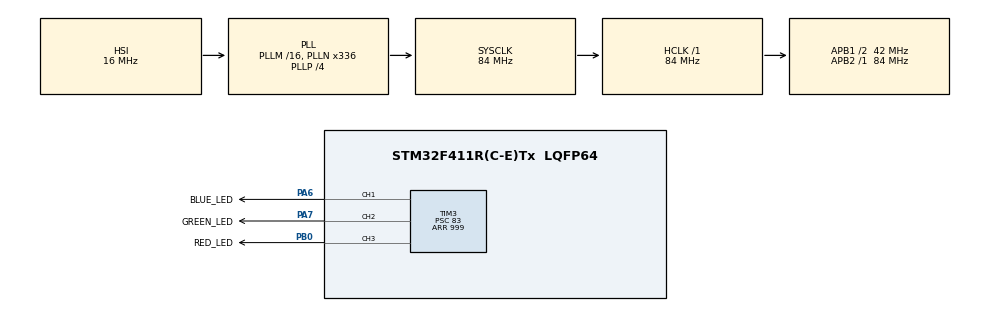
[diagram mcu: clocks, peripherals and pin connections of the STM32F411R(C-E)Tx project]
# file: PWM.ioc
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Mcu.Family=STM32F4
Mcu.Name=STM32F411R(C-E)Tx
Mcu.Package=LQFP64
NVIC.PriorityGroup=NVIC_PRIORITYGROUP_0
PA6.GPIO_Label=BLUE_LED
PA6.Signal=S_TIM3_CH1
PA7.GPIO_Label=GREEN_LED
PA7.Signal=S_TIM3_CH2
PB0.GPIO_Label=RED_LED
PB0.Signal=S_TIM3_CH3
ProjectManager.HeapSize=0x200
ProjectManager.StackSize=0x400
ProjectManager.TargetToolchain=STM32CubeIDE
RCC.48MHZClocksFreq_Value=84000000
RCC.AHBFreq_Value=84000000
RCC.APB1CLKDivider=RCC_HCLK_DIV2
RCC.APB1Freq_Value=42000000
RCC.APB1TimFreq_Value=84000000
RCC.APB2Freq_Value=84000000
RCC.APB2TimFreq_Value=84000000
RCC.CortexFreq_Value=84000000
RCC.FLatency-AdvancedSettings=FLASH_LATENCY_2
RCC.HCLKFreq_Value=84000000
RCC.HSE_VALUE=8000000
RCC.HSI_VALUE=16000000
RCC.PLLN=336
RCC.PLLP=RCC_PLLP_DIV4
RCC.SYSCLKFreq_VALUE=84000000
RCC.SYSCLKSource=RCC_SYSCLKSOURCE_PLLCLK
RCC.VCOOutputFreq_Value=336000000
SH.S_TIM3_CH1.0=TIM3_CH1,PWM Generation1 CH1
SH.S_TIM3_CH2.0=TIM3_CH2,PWM Generation2 CH2
SH.S_TIM3_CH3.0=TIM3_CH3,PWM Generation3 CH3
TIM3.AutoReloadPreload=TIM_AUTORELOAD_PRELOAD_ENABLE
TIM3.Channel-PWM\ Generation1\ CH1=TIM_CHANNEL_1
TIM3.Channel-PWM\ Generation2\ CH2=TIM_CHANNEL_2
TIM3.Channel-PWM\ Generation3\ CH3=TIM_CHANNEL_3
TIM3.Period=999
TIM3.Prescaler=83
board=NUCLEO-F411RE

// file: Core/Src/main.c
/* USER CODE BEGIN Header */
/**
  ******************************************************************************
  * @file           : main.c
  * @brief          : Main program body
  ******************************************************************************
  * @attention
  *
  * Copyright (c) 2026 STMicroelectronics.
  * All rights reserved.
  *
  * This software is licensed under terms that can be found in the LICENSE file
  * in the root directory of this software component.
  * If no LICENSE file comes with this software, it is provided AS-IS.
  *
  ******************************************************************************
  */
/* USER CODE END Header */
#include "main.h"

TIM_HandleTypeDef htim3;

void SystemClock_Config(void);
static void MX_GPIO_Init(void);
static void MX_TIM3_Init(void);

int main(void)
{

  /* MCU Configuration--------------------------------------------------------*/

  /* Reset of all peripherals, Initializes the Flash interface and the Systick. */
  HAL_Init();

  /* Configure the system clock */
  SystemClock_Config();

  /* Initialize all configured peripherals */
  MX_GPIO_Init();
  MX_TIM3_Init();
  /* USER CODE BEGIN 2 */

  HAL_TIM_PWM_Start(&htim3, TIM_CHANNEL_1);
  HAL_TIM_PWM_Start(&htim3, TIM_CHANNEL_2);
  HAL_TIM_PWM_Start(&htim3, TIM_CHANNEL_3);

  /* USER CODE END 2 */

  /* Infinite loop */

  while (1)
	  /* USER CODE BEGIN WHILE */
  {
	  for(int i = 0; i < 1000; i++)
	   {
	     __HAL_TIM_SET_COMPARE(&htim3, TIM_CHANNEL_1, i);        // Red ↑
	     __HAL_TIM_SET_COMPARE(&htim3, TIM_CHANNEL_2, 999 - i);  // Green ↓
	     __HAL_TIM_SET_COMPARE(&htim3, TIM_CHANNEL_3, i / 2);    // Blue medium

	     HAL_Delay(5);
	   }
  }
    /* USER CODE END WHILE */

}

void SystemClock_Config(void)
{
  RCC_OscInitTypeDef RCC_OscInitStruct = {0};
  RCC_ClkInitTypeDef RCC_ClkInitStruct = {0};

  /** Configure the main internal regulator output voltage
  */
  __HAL_RCC_PWR_CLK_ENABLE();
  __HAL_PWR_VOLTAGESCALING_CONFIG(PWR_REGULATOR_VOLTAGE_SCALE1);

  /** Initializes the RCC Oscillators according to the specified parameters
  * in the RCC_OscInitTypeDef structure.
  */
  RCC_OscInitStruct.OscillatorType = RCC_OSCILLATORTYPE_HSI;
  RCC_OscInitStruct.HSIState = RCC_HSI_ON;
  RCC_OscInitStruct.HSICalibrationValue = RCC_HSICALIBRATION_DEFAULT;
  RCC_OscInitStruct.PLL.PLLState = RCC_PLL_ON;
  RCC_OscInitStruct.PLL.PLLSource = RCC_PLLSOURCE_HSI;
  RCC_OscInitStruct.PLL.PLLM = 16;
  RCC_OscInitStruct.PLL.PLLN = 336;
  RCC_OscInitStruct.PLL.PLLP = RCC_PLLP_DIV4;
  RCC_OscInitStruct.PLL.PLLQ = 4;
  if (HAL_RCC_OscConfig(&RCC_OscInitStruct) != HAL_OK)
  {
    Error_Handler();
  }

  /** Initializes the CPU, AHB and APB buses clocks
  */
  RCC_ClkInitStruct.ClockType = RCC_CLOCKTYPE_HCLK|RCC_CLOCKTYPE_SYSCLK
                              |RCC_CLOCKTYPE_PCLK1|RCC_CLOCKTYPE_PCLK2;
  RCC_ClkInitStruct.SYSCLKSource = RCC_SYSCLKSOURCE_PLLCLK;
  RCC_ClkInitStruct.AHBCLKDivider = RCC_SYSCLK_DIV1;
  RCC_ClkInitStruct.APB1CLKDivider = RCC_HCLK_DIV2;
  RCC_ClkInitStruct.APB2CLKDivider = RCC_HCLK_DIV1;

  if (HAL_RCC_ClockConfig(&RCC_ClkInitStruct, FLASH_LATENCY_2) != HAL_OK)
  {
    Error_Handler();
  }
}

static void MX_TIM3_Init(void)
{

  TIM_MasterConfigTypeDef sMasterConfig = {0};
  TIM_OC_InitTypeDef sConfigOC = {0};

  htim3.Instance = TIM3;
  htim3.Init.Prescaler = 83;
  htim3.Init.CounterMode = TIM_COUNTERMODE_UP;
  htim3.Init.Period = 999;
  htim3.Init.ClockDivision = TIM_CLOCKDIVISION_DIV1;
  htim3.Init.AutoReloadPreload = TIM_AUTORELOAD_PRELOAD_ENABLE;
  if (HAL_TIM_PWM_Init(&htim3) != HAL_OK)
  {
    Error_Handler();
  }
  sMasterConfig.MasterOutputTrigger = TIM_TRGO_RESET;
  sMasterConfig.MasterSlaveMode = TIM_MASTERSLAVEMODE_DISABLE;
  if (HAL_TIMEx_MasterConfigSynchronization(&htim3, &sMasterConfig) != HAL_OK)
  {
    Error_Handler();
  }
  sConfigOC.OCMode = TIM_OCMODE_PWM1;
  sConfigOC.Pulse = 0;
  sConfigOC.OCPolarity = TIM_OCPOLARITY_HIGH;
  sConfigOC.OCFastMode = TIM_OCFAST_DISABLE;
  if (HAL_TIM_PWM_ConfigChannel(&htim3, &sConfigOC, TIM_CHANNEL_1) != HAL_OK)
  {
    Error_Handler();
  }
  if (HAL_TIM_PWM_ConfigChannel(&htim3, &sConfigOC, TIM_CHANNEL_2) != HAL_OK)
  {
    Error_Handler();
  }
  if (HAL_TIM_PWM_ConfigChannel(&htim3, &sConfigOC, TIM_CHANNEL_3) != HAL_OK)
  {
    Error_Handler();
  }
  HAL_TIM_MspPostInit(&htim3);

}

static void MX_GPIO_Init(void)
{

  /* GPIO Ports Clock Enable */
  __HAL_RCC_GPIOA_CLK_ENABLE();
  __HAL_RCC_GPIOB_CLK_ENABLE();

}

void Error_Handler(void)
{
  __disable_irq();
  while (1)
  {
  }
}
